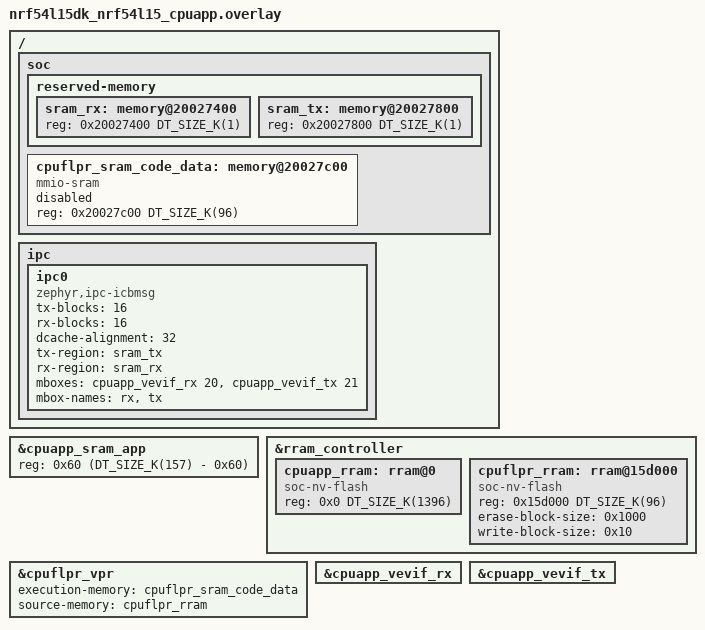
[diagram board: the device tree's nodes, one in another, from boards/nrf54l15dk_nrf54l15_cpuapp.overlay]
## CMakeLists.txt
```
#
# Copyright (c) 2026 Nordic Semiconductor ASA
#
# SPDX-License-Identifier: Apache-2.0
#

cmake_minimum_required(VERSION 3.28.0)

find_package(Zephyr REQUIRED HINTS $ENV{ZEPHYR_BASE})
project(shell_remote_test)

target_sources(app PRIVATE src/main.c)
```

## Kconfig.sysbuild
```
#
# Copyright (c) 2026 Nordic Semiconductor ASA
#
# SPDX-License-Identifier: Apache-2.0
#

config REMOTE_BOARD
	string
	default "$(BOARD)/nrf5340/cpunet" if BOARD_NRF5340DK_NRF5340_CPUAPP
	default "$(BOARD)/nrf5340/cpunet" if BOARD_NRF5340DK_NRF5340_CPUAPP_NS
	default "$(BOARD)/nrf5340/cpunet" if BOARD_NRF5340BSIM_NRF5340_CPUAPP
	default "$(BOARD)/nrf54l15/cpuflpr" if SOC_NRF54L15_CPUAPP

source "share/sysbuild/Kconfig"
```

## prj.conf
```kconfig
CONFIG_ZTEST=y

CONFIG_IPC_SERVICE=y
CONFIG_MBOX=y

CONFIG_LOG=y
CONFIG_LOG_PRINTK=n
CONFIG_ASSERT=y

CONFIG_SHELL=y
CONFIG_SHELL_REMOTE=y
CONFIG_SHELL_BACKEND_DUMMY=y
CONFIG_SHELL_BACKEND_SERIAL=n
CONFIG_SHELL_VT100_COLORS=n
CONFIG_HEAP_MEM_POOL_SIZE=1024
```

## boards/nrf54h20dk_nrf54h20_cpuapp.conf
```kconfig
# Copyright (c) 2026 Nordic Semiconductor ASA
# SPDX-License-Identifier: Apache-2.0

# Boot the Radio core (CPURAD); devicetree IPC to CPURAD is enabled in board DTS.
CONFIG_SOC_NRF54H20_CPURAD_ENABLE=y
CONFIG_SHELL_REMOTE_PPR=y
CONFIG_SHELL_REMOTE_FLPR=y
CONFIG_SHELL_REMOTE_RADIO=y
```

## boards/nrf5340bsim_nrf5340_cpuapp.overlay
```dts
/*
 * Copyright (c) 2026 Nordic Semiconductor ASA
 *
 * SPDX-License-Identifier: Apache-2.0
 */

#include "nrf5340dk_nrf5340_cpuapp.overlay"
```

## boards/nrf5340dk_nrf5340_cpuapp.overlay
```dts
/*
 * Copyright (c) 2026 Nordic Semiconductor ASA
 *
 * SPDX-License-Identifier: Apache-2.0
 */

/ {
	chosen {
		/delete-property/ zephyr,ipc_shm;
	};

	reserved-memory {
		#address-cells = <1>;
		#size-cells = <1>;

		/delete-node/ memory@20070000;

		sram_tx: memory@20070000 {
			reg = <0x20070000 0x0800>;
		};

		sram_rx: memory@20078000 {
			reg = <0x20078000 0x0800>;
		};
	};

	ipc {
		/delete-node/ ipc0;

		ipc0: ipc0 {
			compatible = "zephyr,ipc-icmsg";
			tx-region = <&sram_tx>;
			rx-region = <&sram_rx>;
			mboxes = <&mbox 0>, <&mbox 1>;
			mbox-names = "tx", "rx";
			status = "okay";

			bt_hci_ipc0: bt_hci_ipc0 {
				compatible = "zephyr,bt-hci-ipc";
				status = "okay";
			};
		};
	};
};
```

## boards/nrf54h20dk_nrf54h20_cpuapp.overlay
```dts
/*
 * Copyright (c) 2026 Nordic Semiconductor ASA
 *
 * SPDX-License-Identifier: Apache-2.0
 */

&cpuapp_cpuppr_ipc {
	status = "okay";
};

&cpuapp_cpuflpr_ipc {
	status = "okay";
};

&cpuppr_vevif {
	status = "okay";
};

&cpuflpr_vevif {
	status = "okay";
};

&cpuppr_vpr {
	status = "okay";
};

&cpuflpr_vpr {
	status = "okay";
};
```

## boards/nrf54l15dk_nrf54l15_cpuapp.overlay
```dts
/*
 * Copyright (c) 2026 Nordic Semiconductor ASA
 *
 * SPDX-License-Identifier: Apache-2.0
 */

/* 256k RAM layout:
 * - 157k APP RAM
 * - 2k APP-FLPR IPC communication
 * - 96k FLPR Code
 * - 1k FLPR Hibernation space
 */

/ {
	soc {
		reserved-memory {
			#address-cells = <1>;
			#size-cells = <1>;

			sram_rx: memory@20027400 {
				reg = <0x20027400 DT_SIZE_K(1)>;
			};

			sram_tx: memory@20027800 {
				reg = <0x20027800 DT_SIZE_K(1)>;
			};
		};

		cpuflpr_sram_code_data: memory@20027c00 {
			compatible = "mmio-sram";
			reg = <0x20027c00 DT_SIZE_K(96)>;
			ranges = <0x0 0x20027c00 DT_SIZE_K(96)>;
			status = "reserved";
			#address-cells = <1>;
			#size-cells = <1>;
		};
	};

	ipc {
		ipc0: ipc0 {
			compatible = "zephyr,ipc-icbmsg";
			tx-blocks = <16>;
			rx-blocks = <16>;
			dcache-alignment = <32>;
			tx-region = <&sram_tx>;
			rx-region = <&sram_rx>;
			mboxes = <&cpuapp_vevif_rx 20>, <&cpuapp_vevif_tx 21>;
			mbox-names = "rx", "tx";
			status = "okay";
		};
	};
};

&cpuapp_sram_app {
	reg = <0x60 (DT_SIZE_K(157) - 0x60)>;
};

&rram_controller {
	cpuapp_rram: rram@0 {
		compatible = "soc-nv-flash";
		reg = <0x0 DT_SIZE_K(1396)>;
		ranges = <0x0 0 DT_SIZE_K(1396)>;
	};

	cpuflpr_rram: rram@15d000 {
		compatible = "soc-nv-flash";
		reg = <0x15d000 DT_SIZE_K(96)>;
		ranges = <0x0 0x15d000 DT_SIZE_K(96)>;
		erase-block-size = <0x1000>;
		write-block-size = <0x10>;
		#address-cells = <1>;
		#size-cells = <1>;
	};
};

&cpuflpr_vpr {
	status = "okay";
	execution-memory = <&cpuflpr_sram_code_data>;
	source-memory = <&cpuflpr_rram>;
};

&cpuapp_vevif_rx {
	status = "okay";
};

&cpuapp_vevif_tx {
	status = "okay";
};
```

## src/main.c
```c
/*
 * Copyright (c) 2026 Nordic Semiconductor ASA
 *
 * SPDX-License-Identifier: Apache-2.0
 */

#include <zephyr/tc_util.h>
#include <zephyr/kernel.h>
#include <zephyr/ztest.h>
#include <zephyr/shell/shell.h>
#include <zephyr/shell/shell_dummy.h>
#include <zephyr/shell/shell_remote.h>
#include <stdio.h>
#include <stdlib.h>
#include <string.h>

/* Wait for command completion */
#define SLEEP_TIME 50

static char *remote_names[8];
static char *remote_name;
static size_t remote_names_count;

/* Parse shell response to tab suggestion to get remote names */
static void get_remote_names(void)
{
	if (!IS_ENABLED(CONFIG_SHELL_REMOTE_MULTI_CLI)) {
		remote_names[remote_names_count] = "";
		remote_names_count++;
		TC_PRINT("Single remote client\n");
		return;
	}

	STRUCT_SECTION_FOREACH(shell_remote, remote) {
		size_t remote_name_len = strlen(remote->name);

		remote_names[remote_names_count] = (char *)malloc(remote_name_len + 2);
		remote_names[remote_names_count][0] = ' ';
		memcpy((void *)&remote_names[remote_names_count][1], remote->name, remote_name_len);
		remote_names[remote_names_count][remote_name_len + 1] = '\0';
		remote_names_count++;
		zassert_true(remote_names_count < ARRAY_SIZE(remote_names),
			     "Remote names count is too large: %d", remote_names_count);
	}

	if (remote_names_count == 0) {
		zassert_true(remote_names_count > 0, "At least one remote name should be found");
	}

	TC_PRINT("remote names:");
	for (int i = 0; i < remote_names_count; i++) {
		TC_PRINT(" %s", remote_names[i]);
	}
	TC_PRINT("\n");
}

static int cmd_ping(const struct shell *sh, size_t argc, char **argv)
{
	ARG_UNUSED(argc);
	ARG_UNUSED(argv);

	shell_print(sh, "pong");
	return 0;
}

SHELL_CMD_REGISTER(ping, NULL, "Basic remote shell command", cmd_ping);

static void test_shell_execute_cmd(const char *cmd, int result, const char *expected,
				   size_t expected_len)
{
	const struct shell *sh = shell_backend_dummy_get_ptr();
	int ret;
	size_t len;

	shell_backend_dummy_clear_output(sh);

	ret = shell_execute_cmd(sh, cmd);

	TC_PRINT("shell command executed: \"%s\" returned: %d\n", cmd, ret);
	zassert_true(ret == result, "cmd: %s, got:%d, expected:%d", cmd, ret, result);
	k_msleep(SLEEP_TIME);

	const char *str = shell_backend_dummy_get_output(sh, &len);

	zassert_equal(len, expected_len, "len: %d, expected_len:%d response:%s", len, expected_len,
		      str);
	zassert_mem_equal(str, expected, expected_len, "cmd: %s, got:%s, expected:%s", cmd, str,
			  expected);
	shell_backend_dummy_clear_output(sh);
}

ZTEST(shell_remote, test_local_cmd)
{
#define PING_RESP "\r\npong\r\n"

	const struct shell *sh = shell_backend_dummy_get_ptr();

	zassert_not_null(sh, "dummy shell backend is not available");
	zassert_true(shell_ready(sh), "timed out waiting for dummy shell backend");

	test_shell_execute_cmd("ping", 0, PING_RESP, sizeof(PING_RESP) - 1);
}

ZTEST(shell_remote, test_remote_ping)
{
#define PING_RESP    "\r\npong\r\n"
#define PING_COMMAND "remote_shell%s ping"
	char command[sizeof(PING_COMMAND) + 64];
	int rv;

	rv = snprintf(command, sizeof(command), PING_COMMAND, remote_name);
	zassert_true(rv > 0);

	test_shell_execute_cmd(command, 0, PING_RESP, sizeof(PING_RESP) - 1);
}

ZTEST(shell_remote, test_local_tab)
{
	const struct shell *sh = shell_backend_dummy_get_ptr();
	int rv;
	size_t len;

	shell_backend_dummy_clear_output(sh);
	shell_backend_dummy_clear_input(sh);
	rv = shell_backend_dummy_push_input(sh, "\t", 1);
	k_msleep(SLEEP_TIME);

	const char *str = shell_backend_dummy_get_output(sh, &len);

	/* Expect to find the remote shell command. */
	zassert_not_null(strstr(str, "remote_shell"));

	(void)shell_backend_dummy_push_input(sh, "\r\n", 2);
	k_msleep(SLEEP_TIME);

	shell_backend_dummy_clear_output(sh);
}

static void clear_shell(void)
{
	const struct shell *sh = shell_backend_dummy_get_ptr();
	const char ctrl_c = 0x03;

	shell_backend_dummy_clear_input(sh);
	zassert_true(IS_ENABLED(CONFIG_SHELL_METAKEYS), "shell metakeys are not enabled");
	(void)shell_backend_dummy_push_input(sh, &ctrl_c, 1);
	k_msleep(SLEEP_TIME);
	shell_backend_dummy_clear_output(sh);
}

ZTEST(shell_remote, test_remote_tab)
{
#undef TAB_COMMAND
#define TAB_COMMAND "remote_shell%s \t"
	const struct shell *sh = shell_backend_dummy_get_ptr();
	int rv;
	size_t len;
	char command[sizeof(TAB_COMMAND) + 64];

	rv = snprintf(command, sizeof(command), TAB_COMMAND, remote_name);
	zassert_true(rv > 0);

	shell_backend_dummy_clear_output(sh);

	shell_backend_dummy_push_input(sh, command, strlen(command));
	k_msleep(SLEEP_TIME);

	const char *str = shell_backend_dummy_get_output(sh, &len);

	/* Expect to find the remote shell command. */
	zassert_not_null(strstr(str, "ping"));
}

ZTEST(shell_remote, test_remote_cmd_tab)
{
#undef TAB_COMMAND
#define TAB_COMMAND "remote_shell%s static_cmd \t"
	const struct shell *sh = shell_backend_dummy_get_ptr();
	int rv;
	size_t len;
	char command[sizeof(TAB_COMMAND) + 64];

	rv = snprintf(command, sizeof(command), TAB_COMMAND, remote_name);
	zassert_true(rv > 0);

	shell_backend_dummy_clear_output(sh);

	shell_backend_dummy_push_input(sh, command, strlen(command));
	k_msleep(SLEEP_TIME);

	const char *str = shell_backend_dummy_get_output(sh, &len);

	/* Expect to find the remote shell command. */
	zassert_not_null(strstr(str, "cmd1"), "Failed for remote: %s", remote_name);
	zassert_not_null(strstr(str, "cmd2"), "Failed for remote: %s", remote_name);
	zassert_not_null(strstr(str, "cmd3"), "Failed for remote: %s", remote_name);
	zassert_not_null(strstr(str, "too_long_string_cmd"), "Failed for remote: %s", remote_name);
}

ZTEST(shell_remote, test_remote_too_long_print_message)
{
#define TOO_LONG_COMMAND "remote_shell%s static_cmd too_long_string_cmd"
	const struct shell *sh = shell_backend_dummy_get_ptr();
	size_t len;
	int rv;
	const char *str;
	char command[sizeof(TOO_LONG_COMMAND) + 64];

	rv = snprintf(command, sizeof(command), TOO_LONG_COMMAND, remote_name);
	zassert_true(rv > 0);

	shell_backend_dummy_clear_output(sh);

	shell_backend_dummy_push_input(sh, command, strlen(command));
	k_msleep(SLEEP_TIME);

	rv = shell_execute_cmd(sh, command);
	zassert_equal(rv, 0);

	str = shell_backend_dummy_get_output(sh, &len);
	zassert_not_null(strstr(str, "Buffer size (128) too small"));
}

ZTEST(shell_remote, test_remote_static_cmd3_error_warn)
{
#define TEST_COMMAND "remote_shell%s static_cmd cmd3"
	const struct shell *sh = shell_backend_dummy_get_ptr();
	char command[sizeof(TEST_COMMAND) + 64];
	size_t len;
	int rv;

	rv = snprintf(command, sizeof(command), TEST_COMMAND, remote_name);
	zassert_true(rv > 0);

	shell_backend_dummy_clear_output(sh);
	rv = shell_execute_cmd(sh, command);
	zassert_equal(rv, 0, "cmd3 shell result");

	const char *str = shell_backend_dummy_get_output(sh, &len);

	zassert_not_null(strstr(str, "remote_static_cmd3_err"), "error output missing: %s", str);
	zassert_not_null(strstr(str, "remote_static_cmd3_warn"), "warning output missing: %s", str);
}

ZTEST(shell_remote, test_remote_dyn_cmd_tab)
{
#undef TAB_COMMAND
#define TAB_COMMAND "remote_shell%s dyn_cmd \t"
	const struct shell *sh = shell_backend_dummy_get_ptr();
	int rv;
	size_t len;
	char command[sizeof(TAB_COMMAND) + 64];

	rv = snprintf(command, sizeof(command), TAB_COMMAND, remote_name);
	zassert_true(rv > 0);

	shell_backend_dummy_clear_output(sh);

	shell_backend_dummy_push_input(sh, command, strlen(command));
	k_msleep(SLEEP_TIME);

	const char *str = shell_backend_dummy_get_output(sh, &len);

	zassert_not_null(strstr(str, "sub_cmd_0"),
			 "completion missing sub_cmd_0: %s for remote: %s", str, remote_name);
	zassert_not_null(strstr(str, "sub_cmd_1"),
			 "completion missing sub_cmd_1: %s for remote: %s", str, remote_name);
	zassert_not_null(strstr(str, "sub_cmd_2"),
			 "completion missing sub_cmd_2: %s for remote: %s", str, remote_name);
}

ZTEST(shell_remote, test_remote_execute_cmd2)
{
#define CMD2_COMMAND "remote_shell%s static_cmd cmd2 argument1"
#define CMD2_RESP    "\r\ncmd2 executed with arg: argument1\r\n"
	char command[sizeof(CMD2_COMMAND) + 64];
	int rv;

	rv = snprintf(command, sizeof(command), CMD2_COMMAND, remote_name);
	zassert_true(rv > 0);

	test_shell_execute_cmd(command, 0, CMD2_RESP, sizeof(CMD2_RESP) - 1);
}

ZTEST(shell_remote, test_remote_dynamic_subcmd)
{
#define DYN_RESP    "\r\nsub_cmd_1\r\n"
#define DYN_COMMAND "remote_shell%s dyn_cmd sub_cmd_1"
	char command[sizeof(DYN_COMMAND) + 64];
	int rv;

	rv = snprintf(command, sizeof(command), DYN_COMMAND, remote_name);
	zassert_true(rv > 0);

	test_shell_execute_cmd(command, 0, DYN_RESP, sizeof(DYN_RESP) - 1);
}

ZTEST(shell_remote, test_remote_print_uint64_t)
{
#define CMD1_COMMAND "remote_shell%s static_cmd cmd1"
#define CMD1_RESP    "\r\ncmd1 executed 12345678901234 1234567890\r\n"
	char command[sizeof(CMD1_COMMAND) + 64];
	int rv;

	rv = snprintf(command, sizeof(command), CMD1_COMMAND, remote_name);
	zassert_true(rv > 0);

	test_shell_execute_cmd(command, 0, CMD1_RESP, sizeof(CMD1_RESP) - 1);
}

static void *remote_shell_setup(void)
{
	static int cli;

	remote_name = remote_names[cli];
	TC_PRINT("Running suite with \"%s\" remote client\n", remote_name);
	cli++;
	return NULL;
}

static void setup(void *arg)
{
	ARG_UNUSED(arg);
	clear_shell();
}

ZTEST_SUITE(shell_remote, NULL, remote_shell_setup, setup, NULL, NULL);

void test_main(void)
{
	get_remote_names();
	ztest_run_all(NULL, false, remote_names_count, 1);
	ztest_verify_all_test_suites_ran();
}
```
